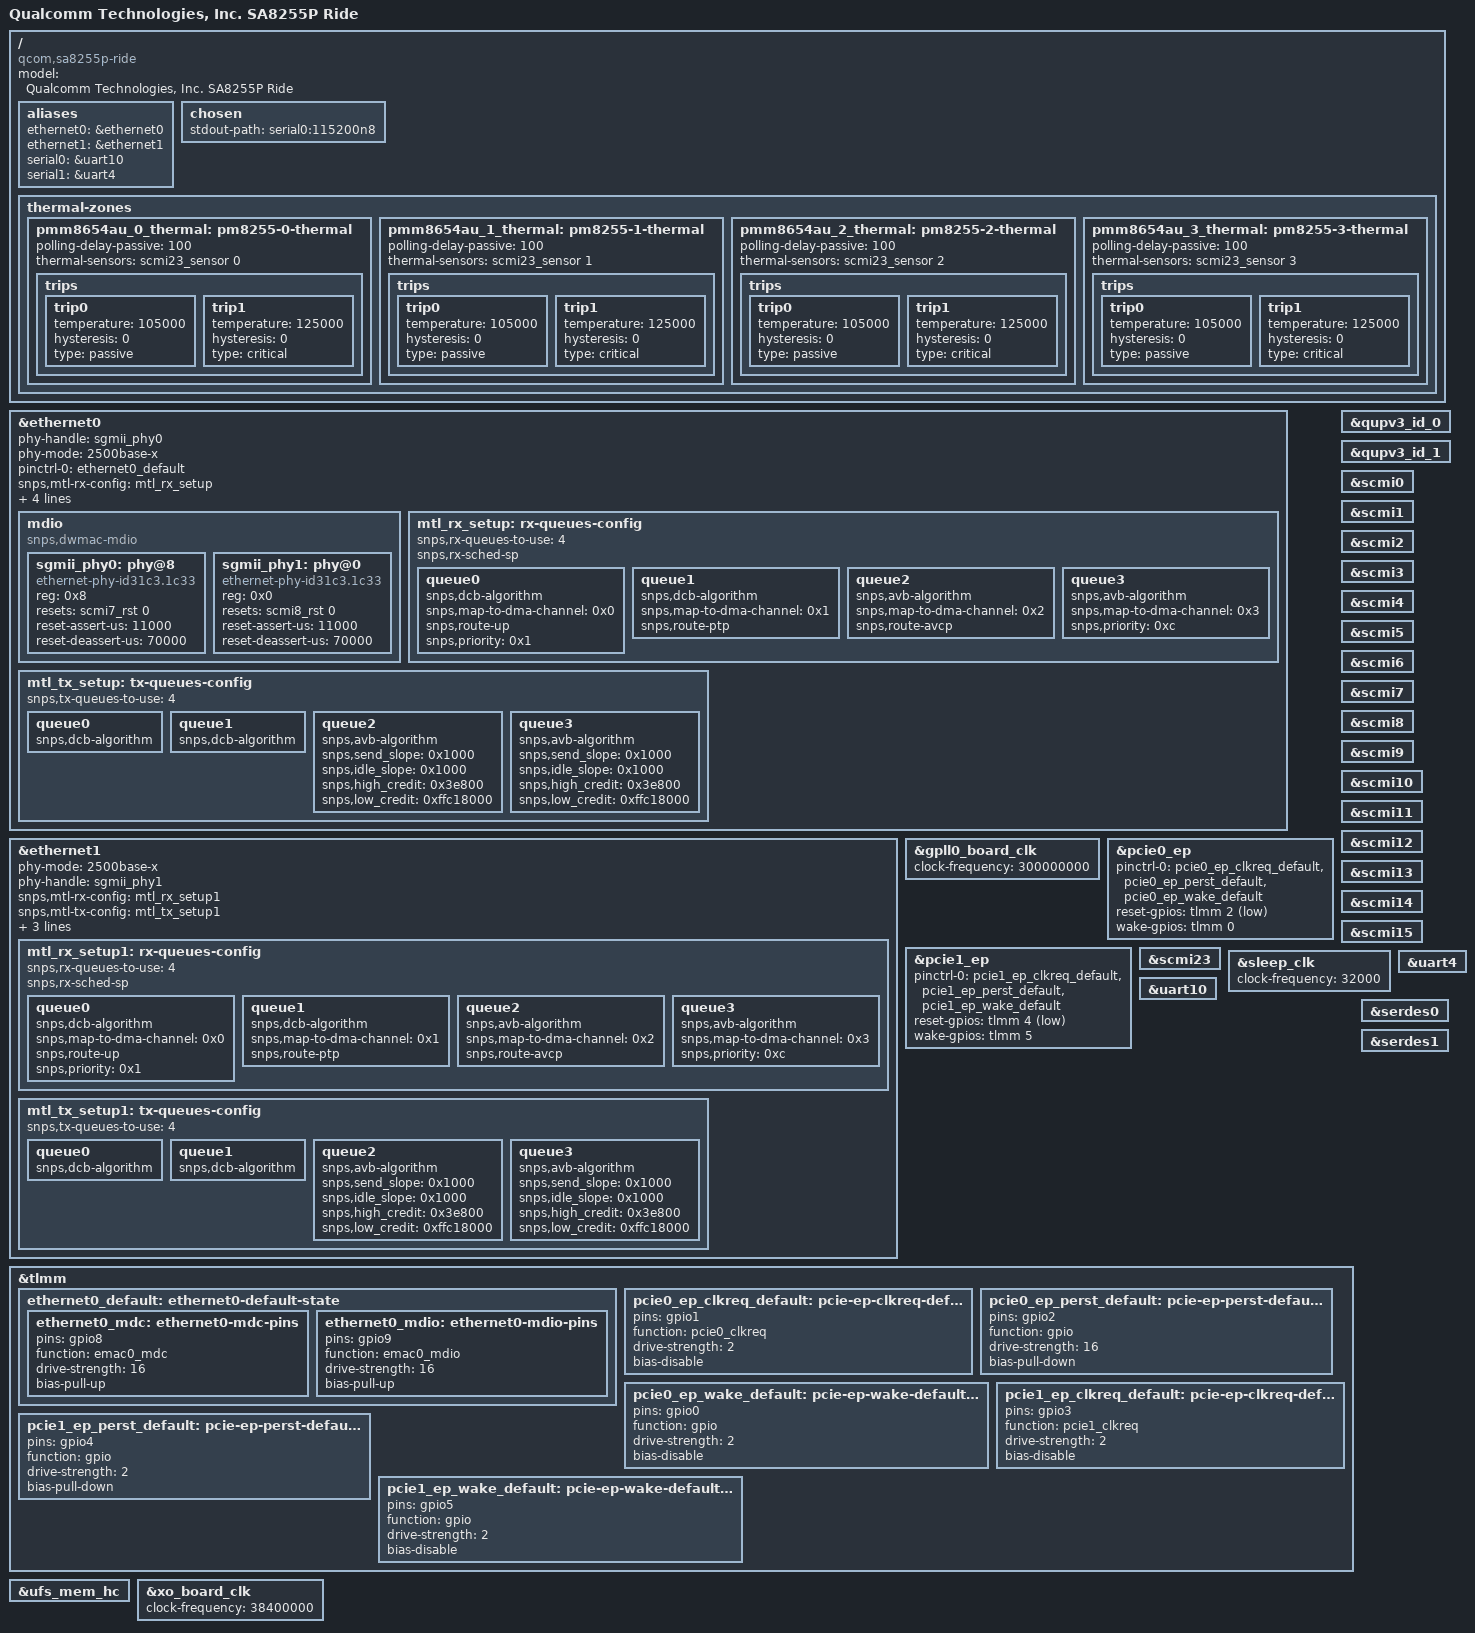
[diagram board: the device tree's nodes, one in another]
// SPDX-License-Identifier: BSD-3-Clause
/*
 * Copyright (c) Qualcomm Technologies, Inc. and/or its subsidiaries.
 */

/dts-v1/;

#include <dt-bindings/gpio/gpio.h>

#include "sa8255p.dtsi"

/ {
	model = "Qualcomm Technologies, Inc. SA8255P Ride";
	compatible = "qcom,sa8255p-ride", "qcom,sa8255p";

	aliases {
		ethernet0 = &ethernet0;
		ethernet1 = &ethernet1;
		serial0 = &uart10;
		serial1 = &uart4;
	};

	chosen {
		stdout-path = "serial0:115200n8";
	};

	thermal-zones {
		pmm8654au_0_thermal: pm8255-0-thermal {
			polling-delay-passive = <100>;
			thermal-sensors = <&scmi23_sensor 0>;

			trips {
				trip0 {
					temperature = <105000>;
					hysteresis = <0>;
					type = "passive";
				};

				trip1 {
					temperature = <125000>;
					hysteresis = <0>;
					type = "critical";
				};
			};
		};

		pmm8654au_1_thermal: pm8255-1-thermal {
			polling-delay-passive = <100>;
			thermal-sensors = <&scmi23_sensor 1>;

			trips {
				trip0 {
					temperature = <105000>;
					hysteresis = <0>;
					type = "passive";
				};

				trip1 {
					temperature = <125000>;
					hysteresis = <0>;
					type = "critical";
				};
			};
		};

		pmm8654au_2_thermal: pm8255-2-thermal {
			polling-delay-passive = <100>;
			thermal-sensors = <&scmi23_sensor 2>;

			trips {
				trip0 {
					temperature = <105000>;
					hysteresis = <0>;
					type = "passive";
				};

				trip1 {
					temperature = <125000>;
					hysteresis = <0>;
					type = "critical";
				};
			};
		};

		pmm8654au_3_thermal: pm8255-3-thermal {
			polling-delay-passive = <100>;
			thermal-sensors = <&scmi23_sensor 3>;

			trips {
				trip0 {
					temperature = <105000>;
					hysteresis = <0>;
					type = "passive";
				};

				trip1 {
					temperature = <125000>;
					hysteresis = <0>;
					type = "critical";
				};
			};
		};
	};
};

&ethernet0 {
	phy-handle = <&sgmii_phy0>;
	phy-mode = "2500base-x";

	pinctrl-0 = <&ethernet0_default>;
	pinctrl-names = "default";

	snps,mtl-rx-config = <&mtl_rx_setup>;
	snps,mtl-tx-config = <&mtl_tx_setup>;
	snps,ps-speed = <2500>;

	power-domains = <&scmi7_pd 0>, <&scmi7_pd 1>;
	power-domain-names = "core", "mdio";

	phys = <&serdes0>;
	phy-names = "serdes";

	status = "okay";

	mdio {
		compatible = "snps,dwmac-mdio";
		#address-cells = <1>;
		#size-cells = <0>;

		sgmii_phy0: phy@8 {
			compatible = "ethernet-phy-id31c3.1c33";
			reg = <0x8>;
			device_type = "ethernet-phy";
			resets = <&scmi7_rst 0>;
			reset-names = "phy";
			reset-assert-us = <11000>;
			reset-deassert-us = <70000>;
		};

		sgmii_phy1: phy@0 {
			compatible = "ethernet-phy-id31c3.1c33";
			reg = <0x0>;
			device_type = "ethernet-phy";
			resets = <&scmi8_rst 0>;
			reset-names = "phy";
			reset-assert-us = <11000>;
			reset-deassert-us = <70000>;
		};
	};

	mtl_rx_setup: rx-queues-config {
		snps,rx-queues-to-use = <4>;
		snps,rx-sched-sp;

		queue0 {
			snps,dcb-algorithm;
			snps,map-to-dma-channel = <0x0>;
			snps,route-up;
			snps,priority = <0x1>;
		};

		queue1 {
			snps,dcb-algorithm;
			snps,map-to-dma-channel = <0x1>;
			snps,route-ptp;
		};

		queue2 {
			snps,avb-algorithm;
			snps,map-to-dma-channel = <0x2>;
			snps,route-avcp;
		};

		queue3 {
			snps,avb-algorithm;
			snps,map-to-dma-channel = <0x3>;
			snps,priority = <0xc>;
		};
	};

	mtl_tx_setup: tx-queues-config {
		snps,tx-queues-to-use = <4>;

		queue0 {
			snps,dcb-algorithm;
		};

		queue1 {
			snps,dcb-algorithm;
		};

		queue2 {
			snps,avb-algorithm;
			snps,send_slope = <0x1000>;
			snps,idle_slope = <0x1000>;
			snps,high_credit = <0x3e800>;
			snps,low_credit = <0xffc18000>;
		};

		queue3 {
			snps,avb-algorithm;
			snps,send_slope = <0x1000>;
			snps,idle_slope = <0x1000>;
			snps,high_credit = <0x3e800>;
			snps,low_credit = <0xffc18000>;
		};
	};
};

&ethernet1 {
	phy-mode = "2500base-x";
	phy-handle = <&sgmii_phy1>;

	snps,mtl-rx-config = <&mtl_rx_setup1>;
	snps,mtl-tx-config = <&mtl_tx_setup1>;
	snps,ps-speed = <2500>;

	power-domains = <&scmi8_pd 0>, <&scmi8_pd 1>;
	power-domain-names = "core", "mdio";

	phys = <&serdes1>;
	phy-names = "serdes";

	status = "okay";

	mtl_rx_setup1: rx-queues-config {
		snps,rx-queues-to-use = <4>;
		snps,rx-sched-sp;

		queue0 {
			snps,dcb-algorithm;
			snps,map-to-dma-channel = <0x0>;
			snps,route-up;
			snps,priority = <0x1>;
		};

		queue1 {
			snps,dcb-algorithm;
			snps,map-to-dma-channel = <0x1>;
			snps,route-ptp;
		};

		queue2 {
			snps,avb-algorithm;
			snps,map-to-dma-channel = <0x2>;
			snps,route-avcp;
		};

		queue3 {
			snps,avb-algorithm;
			snps,map-to-dma-channel = <0x3>;
			snps,priority = <0xc>;
		};
	};

	mtl_tx_setup1: tx-queues-config {
		snps,tx-queues-to-use = <4>;

		queue0 {
			snps,dcb-algorithm;
		};

		queue1 {
			snps,dcb-algorithm;
		};

		queue2 {
			snps,avb-algorithm;
			snps,send_slope = <0x1000>;
			snps,idle_slope = <0x1000>;
			snps,high_credit = <0x3e800>;
			snps,low_credit = <0xffc18000>;
		};

		queue3 {
			snps,avb-algorithm;
			snps,send_slope = <0x1000>;
			snps,idle_slope = <0x1000>;
			snps,high_credit = <0x3e800>;
			snps,low_credit = <0xffc18000>;
		};
	};
};

&gpll0_board_clk {
	clock-frequency = <300000000>;
};

&pcie0_ep {
	pinctrl-names = "default";
	pinctrl-0 = <&pcie0_ep_clkreq_default &pcie0_ep_perst_default
		    &pcie0_ep_wake_default>;
	reset-gpios = <&tlmm 2 GPIO_ACTIVE_LOW>;
	wake-gpios = <&tlmm 0 GPIO_ACTIVE_HIGH>;
};

&pcie1_ep {
	pinctrl-names = "default";
	pinctrl-0 = <&pcie1_ep_clkreq_default &pcie1_ep_perst_default
		    &pcie1_ep_wake_default>;
	reset-gpios = <&tlmm 4 GPIO_ACTIVE_LOW>;
	wake-gpios = <&tlmm 5 GPIO_ACTIVE_HIGH>;
};

&qupv3_id_0 {
	status = "okay";
};

&qupv3_id_1 {
	status = "okay";
};

&scmi0 {
	status = "okay";
};

&scmi1 {
	status = "okay";
};

&scmi2 {
	status = "okay";
};

&scmi3 {
	status = "okay";
};

&scmi4 {
	status = "okay";
};

&scmi5 {
	status = "okay";
};

&scmi6 {
	status = "okay";
};

&scmi7 {
	status = "okay";
};

&scmi8 {
	status = "okay";
};

&scmi9 {
	status = "okay";
};

&scmi10 {
	status = "okay";
};

&scmi11 {
	status = "okay";
};

&scmi12 {
	status = "okay";
};

&scmi13 {
	status = "okay";
};

&scmi14 {
	status = "okay";
};

&scmi15 {
	status = "okay";
};

&scmi23 {
	status = "okay";
};

&sleep_clk {
	clock-frequency = <32000>;
};

&uart4 {
	status = "okay";
};

&uart10 {
	status = "okay";
};

&tlmm {
	ethernet0_default: ethernet0-default-state {
		ethernet0_mdc: ethernet0-mdc-pins {
			pins = "gpio8";
			function = "emac0_mdc";
			drive-strength = <16>;
			bias-pull-up;
		};

		ethernet0_mdio: ethernet0-mdio-pins {
			pins = "gpio9";
			function = "emac0_mdio";
			drive-strength = <16>;
			bias-pull-up;
		};
	};

	pcie0_ep_clkreq_default: pcie-ep-clkreq-default-state {
		pins = "gpio1";
		function = "pcie0_clkreq";
		drive-strength = <2>;
		bias-disable;
	};

	pcie0_ep_perst_default: pcie-ep-perst-default-state {
		pins = "gpio2";
		function = "gpio";
		drive-strength = <16>;
		bias-pull-down;
	};

	pcie0_ep_wake_default: pcie-ep-wake-default-state {
		pins = "gpio0";
		function = "gpio";
		drive-strength = <2>;
		bias-disable;
	};

	pcie1_ep_clkreq_default: pcie-ep-clkreq-default-state {
		pins = "gpio3";
		function = "pcie1_clkreq";
		drive-strength = <2>;
		bias-disable;
	};

	pcie1_ep_perst_default: pcie-ep-perst-default-state {
		pins = "gpio4";
		function = "gpio";
		drive-strength = <2>;
		bias-pull-down;
	};

	pcie1_ep_wake_default: pcie-ep-wake-default-state {
		pins = "gpio5";
		function = "gpio";
		drive-strength = <2>;
		bias-disable;
	};
};

&serdes0 {
	status = "okay";
};

&serdes1 {
	status = "okay";
};

&ufs_mem_hc {
	status = "okay";
};

&xo_board_clk {
	clock-frequency = <38400000>;
};
